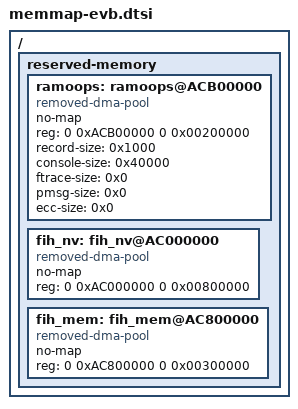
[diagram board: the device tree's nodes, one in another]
/* ref: sdm660.dtsi */

/ {
	reserved-memory {
		ramoops: ramoops@ACB00000 {
			compatible = "removed-dma-pool", "ramoops";
			no-map;
			reg = <0 0xACB00000 0 0x00200000>;
			record-size = <0x1000>;
			console-size = <0x40000>;
			ftrace-size = <0x0>;
			pmsg-size = <0x0>;
			ecc-size = <0x0>;
			status = "ok";
		};
		fih_nv: fih_nv@AC000000 {
			compatible = "removed-dma-pool";
			no-map;
			reg = <0 0xAC000000 0 0x00800000>;
		};
		fih_mem: fih_mem@AC800000 {
			compatible = "removed-dma-pool";
			no-map;
			reg = <0 0xAC800000 0 0x00300000>;
		};
	};
};
